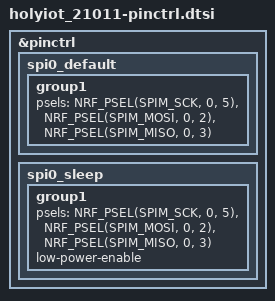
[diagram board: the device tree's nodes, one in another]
/* SPDX-License-Identifier: Apache-2.0 */

/* LIS2DH12 по SPI (схема HOLYIOT-21014 V1.0, разводка совпадает с 21011 v1.0). */
&pinctrl {
	spi0_default: spi0_default {
		group1 {
			psels = <NRF_PSEL(SPIM_SCK, 0, 5)>,
				<NRF_PSEL(SPIM_MOSI, 0, 2)>,
				<NRF_PSEL(SPIM_MISO, 0, 3)>;
		};
	};

	spi0_sleep: spi0_sleep {
		group1 {
			psels = <NRF_PSEL(SPIM_SCK, 0, 5)>,
				<NRF_PSEL(SPIM_MOSI, 0, 2)>,
				<NRF_PSEL(SPIM_MISO, 0, 3)>;
			low-power-enable;
		};
	};
};
